AUTOSAR XML (schema 4-2-2)
package /STELLANTIS/EPT/ASWCs
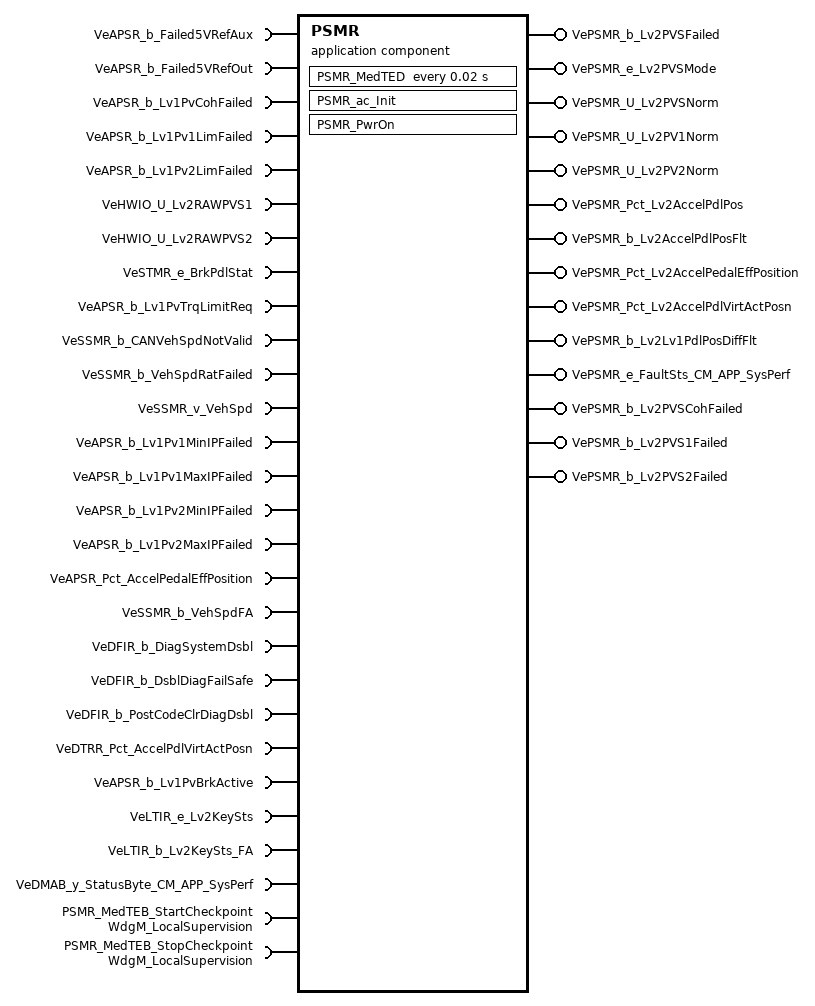
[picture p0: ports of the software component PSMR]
  application sw component type PSMR
    26 x require port:
      VeAPSR_b_Failed5VRefAux: nonqueued-receiver-com-spec{data-element=Value, init-value=0}, required-interface=VeAPSR_b_Failed5VRefAux
      VeAPSR_b_Failed5VRefOut: nonqueued-receiver-com-spec{data-element=Value, init-value=0}, required-interface=VeAPSR_b_Failed5VRefOut
      VeAPSR_b_Lv1PvCohFailed: nonqueued-receiver-com-spec{data-element=Value, init-value=0}, required-interface=VeAPSR_b_Lv1PvCohFailed
      VeAPSR_b_Lv1Pv1LimFailed: nonqueued-receiver-com-spec{data-element=Value, init-value=0}, required-interface=VeAPSR_b_Lv1Pv1LimFailed
      VeAPSR_b_Lv1Pv2LimFailed: nonqueued-receiver-com-spec{data-element=Value, init-value=0}, required-interface=VeAPSR_b_Lv1Pv2LimFailed
      VeHWIO_U_Lv2RAWPVS1: nonqueued-receiver-com-spec{data-element=Value, init-value=0}, required-interface=VeHWIO_U_Lv2RAWPVS1
      VeHWIO_U_Lv2RAWPVS2: nonqueued-receiver-com-spec{data-element=Value, init-value=0}, required-interface=VeHWIO_U_Lv2RAWPVS2
      VeSTMR_e_BrkPdlStat: nonqueued-receiver-com-spec{data-element=Value, init-value=CeSTMR_e_BrkStat_NotDtrmnd}, required-interface=VeSTMR_e_BrkPdlStat
      VeAPSR_b_Lv1PvTrqLimitReq: nonqueued-receiver-com-spec{data-element=Value, init-value=0}, required-interface=VeAPSR_b_Lv1PvTrqLimitReq
      VeSSMR_b_CANVehSpdNotValid: nonqueued-receiver-com-spec{data-element=Value, init-value=0}, required-interface=VeSSMR_b_CANVehSpdNotValid
      VeSSMR_b_VehSpdRatFailed: nonqueued-receiver-com-spec{data-element=Value, init-value=0}, required-interface=VeSSMR_b_VehSpdRatFailed
      VeSSMR_v_VehSpd: nonqueued-receiver-com-spec{data-element=Value, init-value=0}, required-interface=VeSSMR_v_VehSpd
      VeAPSR_b_Lv1Pv1MinIPFailed: nonqueued-receiver-com-spec{data-element=Value, init-value=0}, required-interface=VeAPSR_b_Lv1Pv1MinIPFailed
      VeAPSR_b_Lv1Pv1MaxIPFailed: nonqueued-receiver-com-spec{data-element=Value, init-value=0}, required-interface=VeAPSR_b_Lv1Pv1MaxIPFailed
      VeAPSR_b_Lv1Pv2MinIPFailed: nonqueued-receiver-com-spec{data-element=Value, init-value=0}, required-interface=VeAPSR_b_Lv1Pv2MinIPFailed
      VeAPSR_b_Lv1Pv2MaxIPFailed: nonqueued-receiver-com-spec{data-element=Value, init-value=0}, required-interface=VeAPSR_b_Lv1Pv2MaxIPFailed
      VeAPSR_Pct_AccelPedalEffPosition: nonqueued-receiver-com-spec{data-element=Value, init-value=0}, required-interface=VeAPSR_Pct_AccelPedalEffPosition
      VeSSMR_b_VehSpdFA: nonqueued-receiver-com-spec{data-element=Value, init-value=0}, required-interface=VeSSMR_b_VehSpdFA
      VeDFIR_b_DiagSystemDsbl: nonqueued-receiver-com-spec{data-element=Value, init-value=0}, required-interface=VeDFIR_b_DiagSystemDsbl
      VeDFIR_b_DsblDiagFailSafe: nonqueued-receiver-com-spec{data-element=Value, init-value=0}, required-interface=VeDFIR_b_DsblDiagFailSafe
      VeDFIR_b_PostCodeClrDiagDsbl: nonqueued-receiver-com-spec{data-element=Value, init-value=0}, required-interface=VeDFIR_b_PostCodeClrDiagDsbl
      VeDTRR_Pct_AccelPdlVirtActPosn: nonqueued-receiver-com-spec{data-element=Value, init-value=0}, required-interface=VeDTRR_Pct_AccelPdlVirtActPosn
      VeAPSR_b_Lv1PvBrkActive: nonqueued-receiver-com-spec{data-element=Value, init-value=0}, required-interface=VeAPSR_b_Lv1PvBrkActive
      VeLTIR_e_Lv2KeySts: nonqueued-receiver-com-spec{data-element=Value, init-value=CeLTIR_e_IGN_LK}, required-interface=VeLTIR_e_Lv2KeySts
      VeLTIR_b_Lv2KeySts_FA: nonqueued-receiver-com-spec{data-element=Value, init-value=0}, required-interface=VeLTIR_b_Lv2KeySts_FA
      VeDMAB_y_StatusByte_CM_APP_SysPerf: nonqueued-receiver-com-spec{data-element=Value, init-value=0}, required-interface=VeDMAB_y_StatusByte_CM_APP_SysPerf
    14 x provide port:
      VePSMR_b_Lv2PVSFailed: nonqueued-sender-com-spec{data-element=Value, init-value=0}, provided-interface=VePSMR_b_Lv2PVSFailed
      VePSMR_e_Lv2PVSMode: nonqueued-sender-com-spec{data-element=Value, init-value=CePSMR_e_NO_Fault}, provided-interface=VePSMR_e_Lv2PVSMode
      VePSMR_U_Lv2PVSNorm: nonqueued-sender-com-spec{data-element=Value, init-value=0}, provided-interface=VePSMR_U_Lv2PVSNorm
      VePSMR_U_Lv2PV1Norm: nonqueued-sender-com-spec{data-element=Value, init-value=0}, provided-interface=VePSMR_U_Lv2PV1Norm
      VePSMR_U_Lv2PV2Norm: nonqueued-sender-com-spec{data-element=Value, init-value=0}, provided-interface=VePSMR_U_Lv2PV2Norm
      VePSMR_Pct_Lv2AccelPdlPos: nonqueued-sender-com-spec{data-element=Value, init-value=0}, provided-interface=VePSMR_Pct_Lv2AccelPdlPos
      VePSMR_b_Lv2AccelPdlPosFlt: nonqueued-sender-com-spec{data-element=Value, init-value=0}, provided-interface=VePSMR_b_Lv2AccelPdlPosFlt
      VePSMR_Pct_Lv2AccelPedalEffPosition: nonqueued-sender-com-spec{data-element=Value, init-value=0}, provided-interface=VePSMR_Pct_Lv2AccelPedalEffPosition
      VePSMR_Pct_Lv2AccelPdlVirtActPosn: nonqueued-sender-com-spec{data-element=Value, init-value=0}, provided-interface=VePSMR_Pct_Lv2AccelPdlVirtActPosn
      VePSMR_b_Lv2Lv1PdlPosDiffFlt: nonqueued-sender-com-spec{data-element=Value, init-value=0}, provided-interface=VePSMR_b_Lv2Lv1PdlPosDiffFlt
      VePSMR_e_FaultSts_CM_APP_SysPerf: nonqueued-sender-com-spec{data-element=Value, init-value=CeDFIB_e_Init}, provided-interface=VePSMR_e_FaultSts_CM_APP_SysPerf
      VePSMR_b_Lv2PVSCohFailed: nonqueued-sender-com-spec{data-element=Value, init-value=0}, provided-interface=VePSMR_b_Lv2PVSCohFailed
      VePSMR_b_Lv2PVS1Failed: nonqueued-sender-com-spec{data-element=Value, init-value=0}, provided-interface=VePSMR_b_Lv2PVS1Failed
      VePSMR_b_Lv2PVS2Failed: nonqueued-sender-com-spec{data-element=Value, init-value=0}, provided-interface=VePSMR_b_Lv2PVS2Failed
    require port PSMR_MedTEB_StartCheckpoint: client-com-spec=CheckpointReached, required-interface=WdgM_LocalSupervision
    require port PSMR_MedTEB_StopCheckpoint: client-com-spec=CheckpointReached, required-interface=WdgM_LocalSupervision
    behavior IB_PSMR: data-type-mapping=msADTtoIDTMapping, handle-termination-and-restart=NO-SUPPORT
      timing event Event_MedTED: start-on-event=PSMR_MedTED, period=0.02
      init event Event_PSMR_ac_Init: start-on-event=PSMR_ac_Init
      init event Event_PwrOn: start-on-event=PSMR_PwrOn
      runnable PSMR_ac_Init
        data-send-points:
          access OUT_VePSMR_e_Lv2PVSMode_Value: accessed-variable=VePSMR_e_Lv2PVSMode.Value
          access OUT_VePSMR_e_FaultSts_CM_APP_SysPerf_Value: accessed-variable=VePSMR_e_FaultSts_CM_APP_SysPerf.Value
      runnable PSMR_MedTED
        data-receive-point-by-arguments:
          26 x access:
            IN_VeAPSR_Pct_AccelPedalEffPosition_Value: accessed-variable=VeAPSR_Pct_AccelPedalEffPosition.Value
            IN_VeAPSR_b_Failed5VRefAux_Value: accessed-variable=VeAPSR_b_Failed5VRefAux.Value
            IN_VeAPSR_b_Failed5VRefOut_Value: accessed-variable=VeAPSR_b_Failed5VRefOut.Value
            IN_VeAPSR_b_Lv1Pv1LimFailed_Value: accessed-variable=VeAPSR_b_Lv1Pv1LimFailed.Value
            IN_VeAPSR_b_Lv1Pv1MaxIPFailed_Value: accessed-variable=VeAPSR_b_Lv1Pv1MaxIPFailed.Value
            IN_VeAPSR_b_Lv1Pv1MinIPFailed_Value: accessed-variable=VeAPSR_b_Lv1Pv1MinIPFailed.Value
            IN_VeAPSR_b_Lv1Pv2LimFailed_Value: accessed-variable=VeAPSR_b_Lv1Pv2LimFailed.Value
            IN_VeAPSR_b_Lv1Pv2MaxIPFailed_Value: accessed-variable=VeAPSR_b_Lv1Pv2MaxIPFailed.Value
            IN_VeAPSR_b_Lv1Pv2MinIPFailed_Value: accessed-variable=VeAPSR_b_Lv1Pv2MinIPFailed.Value
            IN_VeAPSR_b_Lv1PvBrkActive_Value: accessed-variable=VeAPSR_b_Lv1PvBrkActive.Value
            IN_VeAPSR_b_Lv1PvCohFailed_Value: accessed-variable=VeAPSR_b_Lv1PvCohFailed.Value
            IN_VeAPSR_b_Lv1PvTrqLimitReq_Value: accessed-variable=VeAPSR_b_Lv1PvTrqLimitReq.Value
            IN_VeDFIR_b_DiagSystemDsbl_Value: accessed-variable=VeDFIR_b_DiagSystemDsbl.Value
            IN_VeDFIR_b_DsblDiagFailSafe_Value: accessed-variable=VeDFIR_b_DsblDiagFailSafe.Value
            IN_VeDFIR_b_PostCodeClrDiagDsbl_Value: accessed-variable=VeDFIR_b_PostCodeClrDiagDsbl.Value
            IN_VeDMAB_y_StatusByte_CM_APP_SysPerf_Value: accessed-variable=VeDMAB_y_StatusByte_CM_APP_SysPerf.Value
            IN_VeDTRR_Pct_AccelPdlVirtActPosn_Value: accessed-variable=VeDTRR_Pct_AccelPdlVirtActPosn.Value
            IN_VeHWIO_U_Lv2RAWPVS1_Value: accessed-variable=VeHWIO_U_Lv2RAWPVS1.Value
            IN_VeHWIO_U_Lv2RAWPVS2_Value: accessed-variable=VeHWIO_U_Lv2RAWPVS2.Value
            IN_VeLTIR_b_Lv2KeySts_FA_Value: accessed-variable=VeLTIR_b_Lv2KeySts_FA.Value
            IN_VeLTIR_e_Lv2KeySts_Value: accessed-variable=VeLTIR_e_Lv2KeySts.Value
            IN_VeSSMR_b_CANVehSpdNotValid_Value: accessed-variable=VeSSMR_b_CANVehSpdNotValid.Value
            IN_VeSSMR_b_VehSpdFA_Value: accessed-variable=VeSSMR_b_VehSpdFA.Value
            IN_VeSSMR_b_VehSpdRatFailed_Value: accessed-variable=VeSSMR_b_VehSpdRatFailed.Value
            IN_VeSSMR_v_VehSpd_Value: accessed-variable=VeSSMR_v_VehSpd.Value
            IN_VeSTMR_e_BrkPdlStat_Value: accessed-variable=VeSTMR_e_BrkPdlStat.Value
        data-send-points:
          14 x access:
            OUT_VePSMR_e_Lv2PVSMode_Value: accessed-variable=VePSMR_e_Lv2PVSMode.Value
            OUT_VePSMR_U_Lv2PVSNorm_Value: accessed-variable=VePSMR_U_Lv2PVSNorm.Value
            OUT_VePSMR_Pct_Lv2AccelPdlPos_Value: accessed-variable=VePSMR_Pct_Lv2AccelPdlPos.Value
            OUT_VePSMR_b_Lv2AccelPdlPosFlt_Value: accessed-variable=VePSMR_b_Lv2AccelPdlPosFlt.Value
            OUT_VePSMR_Pct_Lv2AccelPedalEffPosition_Value: accessed-variable=VePSMR_Pct_Lv2AccelPedalEffPosition.Value
            OUT_VePSMR_Pct_Lv2AccelPdlVirtActPosn_Value: accessed-variable=VePSMR_Pct_Lv2AccelPdlVirtActPosn.Value
            OUT_VePSMR_b_Lv2Lv1PdlPosDiffFlt_Value: accessed-variable=VePSMR_b_Lv2Lv1PdlPosDiffFlt.Value
            OUT_VePSMR_b_Lv2PVSFailed_Value: accessed-variable=VePSMR_b_Lv2PVSFailed.Value
            OUT_VePSMR_U_Lv2PV1Norm_Value: accessed-variable=VePSMR_U_Lv2PV1Norm.Value
            OUT_VePSMR_U_Lv2PV2Norm_Value: accessed-variable=VePSMR_U_Lv2PV2Norm.Value
            OUT_VePSMR_e_FaultSts_CM_APP_SysPerf_Value: accessed-variable=VePSMR_e_FaultSts_CM_APP_SysPerf.Value
            OUT_VePSMR_b_Lv2PVSCohFailed_Value: accessed-variable=VePSMR_b_Lv2PVSCohFailed.Value
            OUT_VePSMR_b_Lv2PVS1Failed_Value: accessed-variable=VePSMR_b_Lv2PVS1Failed.Value
            OUT_VePSMR_b_Lv2PVS2Failed_Value: accessed-variable=VePSMR_b_Lv2PVS2Failed.Value
        sync call SC_PSMR_MedTEB_StartCheckpoint_CheckpointReached: operation=PSMR_MedTEB_StartCheckpoint.CheckpointReached, timeout=1E-06
        sync call SC_PSMR_MedTEB_StopCheckpoint_CheckpointReached: operation=PSMR_MedTEB_StopCheckpoint.CheckpointReached, timeout=1E-06
      runnable PSMR_PwrOn
        data-send-points:
          14 x access:
            OUT_VePSMR_e_Lv2PVSMode_Value: accessed-variable=VePSMR_e_Lv2PVSMode.Value
            OUT_VePSMR_U_Lv2PVSNorm_Value: accessed-variable=VePSMR_U_Lv2PVSNorm.Value
            OUT_VePSMR_Pct_Lv2AccelPdlPos_Value: accessed-variable=VePSMR_Pct_Lv2AccelPdlPos.Value
            OUT_VePSMR_b_Lv2AccelPdlPosFlt_Value: accessed-variable=VePSMR_b_Lv2AccelPdlPosFlt.Value
            OUT_VePSMR_Pct_Lv2AccelPedalEffPosition_Value: accessed-variable=VePSMR_Pct_Lv2AccelPedalEffPosition.Value
            OUT_VePSMR_Pct_Lv2AccelPdlVirtActPosn_Value: accessed-variable=VePSMR_Pct_Lv2AccelPdlVirtActPosn.Value
            OUT_VePSMR_b_Lv2Lv1PdlPosDiffFlt_Value: accessed-variable=VePSMR_b_Lv2Lv1PdlPosDiffFlt.Value
            OUT_VePSMR_b_Lv2PVSFailed_Value: accessed-variable=VePSMR_b_Lv2PVSFailed.Value
            OUT_VePSMR_U_Lv2PV1Norm_Value: accessed-variable=VePSMR_U_Lv2PV1Norm.Value
            OUT_VePSMR_U_Lv2PV2Norm_Value: accessed-variable=VePSMR_U_Lv2PV2Norm.Value
            OUT_VePSMR_e_FaultSts_CM_APP_SysPerf_Value: accessed-variable=VePSMR_e_FaultSts_CM_APP_SysPerf.Value
            OUT_VePSMR_b_Lv2PVSCohFailed_Value: accessed-variable=VePSMR_b_Lv2PVSCohFailed.Value
            OUT_VePSMR_b_Lv2PVS1Failed_Value: accessed-variable=VePSMR_b_Lv2PVS1Failed.Value
            OUT_VePSMR_b_Lv2PVS2Failed_Value: accessed-variable=VePSMR_b_Lv2PVS2Failed.Value
